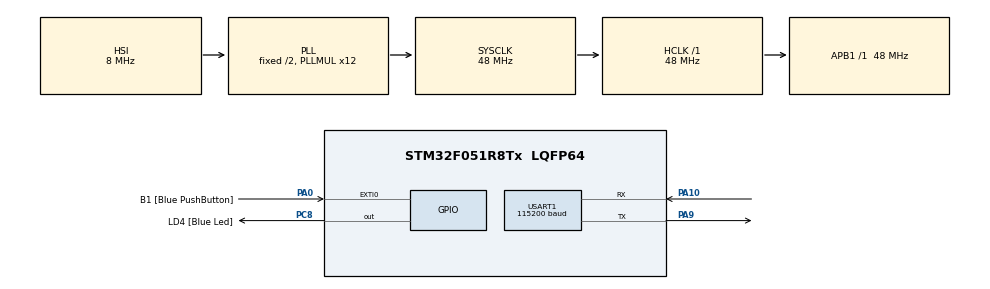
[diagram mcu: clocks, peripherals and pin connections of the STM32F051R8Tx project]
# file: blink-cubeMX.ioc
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Mcu.Family=STM32F0
Mcu.Name=STM32F051R8Tx
Mcu.Package=LQFP64
NVIC.TIM1_BRK_UP_TRG_COM_IRQn=true\:0\:0\:false\:false\:true\:true\:true\:true
PA0.GPIO_Label=B1 [Blue PushButton]
PA0.GPIO_ModeDefaultEXTI=GPIO_MODE_EVT_RISING
PA0.Signal=GPXTI0
PA10.Mode=Asynchronous
PA10.Signal=USART1_RX
PA13.GPIO_Label=SWDIO
PA13.Signal=SYS_SWDIO
PA9.Mode=Asynchronous
PA9.Signal=USART1_TX
PC8.GPIO_Label=LD4 [Blue Led]
PC8.Signal=GPIO_Output
ProjectManager.HeapSize=0x200
ProjectManager.StackSize=0x400
ProjectManager.TargetToolchain=Makefile
RCC.AHBFreq_Value=48000000
RCC.APB1Freq_Value=48000000
RCC.APB1TimFreq_Value=48000000
RCC.HCLKFreq_Value=48000000
RCC.PLLMUL=RCC_PLL_MUL12
RCC.SYSCLKFreq_VALUE=48000000
RCC.SYSCLKSource=RCC_SYSCLKSOURCE_PLLCLK
TIM1.AutoReloadPreload=TIM_AUTORELOAD_PRELOAD_DISABLE
TIM1.Period=65535
TIM1.TIM_MasterOutputTrigger=TIM_TRGO_RESET
USART1.BaudRate=115200
USART1.Mode=MODE_TX
USART1.VirtualMode-Asynchronous=VM_ASYNC
VP_TIM1_VS_ClockSourceINT.Mode=Internal
board=STM32F0DISCOVERY

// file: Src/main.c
/* USER CODE BEGIN Header */
/**
  ******************************************************************************
  * @file           : main.c
  * @brief          : Main program body
  ******************************************************************************
  * @attention
  *
  * Copyright (c) 2024 STMicroelectronics.
  * All rights reserved.
  *
  * This software is licensed under terms that can be found in the LICENSE file
  * in the root directory of this software component.
  * If no LICENSE file comes with this software, it is provided AS-IS.
  *
  ******************************************************************************
  */
/* USER CODE END Header */
#include "main.h"
#include "tim.h"
#include "usart.h"
#include "gpio.h"

void SystemClock_Config(void);

int main(void)
{

  /* MCU Configuration--------------------------------------------------------*/

  /* Reset of all peripherals, Initializes the Flash interface and the Systick. */
  HAL_Init();

  /* Configure the system clock */
  SystemClock_Config();

  /* Initialize all configured peripherals */
  MX_GPIO_Init();
  MX_USART1_UART_Init();
  MX_TIM1_Init();
  /* USER CODE BEGIN 2 */
	HAL_TIM_Base_Start_IT(&htim1);
  /* USER CODE END 2 */

  /* Infinite loop */
  /* USER CODE BEGIN WHILE */
	while (1) {
		HAL_GPIO_WritePin(LD4_GPIO_Port, LD4_Pin, GPIO_PIN_SET);
		printf("[%ld] LED ON\r\n", get_time_ms());
		delay_ms(1000);
		HAL_GPIO_WritePin(LD4_GPIO_Port, LD4_Pin, GPIO_PIN_RESET);
		printf("[%ld] LED OFF\r\n", get_time_ms());
		delay_ms(1000);
    /* USER CODE END WHILE */

	}
}

void SystemClock_Config(void)
{
  RCC_OscInitTypeDef RCC_OscInitStruct = {0};
  RCC_ClkInitTypeDef RCC_ClkInitStruct = {0};
  RCC_PeriphCLKInitTypeDef PeriphClkInit = {0};

  /** Initializes the RCC Oscillators according to the specified parameters
  * in the RCC_OscInitTypeDef structure.
  */
  RCC_OscInitStruct.OscillatorType = RCC_OSCILLATORTYPE_HSI;
  RCC_OscInitStruct.HSIState = RCC_HSI_ON;
  RCC_OscInitStruct.HSICalibrationValue = RCC_HSICALIBRATION_DEFAULT;
  RCC_OscInitStruct.PLL.PLLState = RCC_PLL_ON;
  RCC_OscInitStruct.PLL.PLLSource = RCC_PLLSOURCE_HSI;
  RCC_OscInitStruct.PLL.PLLMUL = RCC_PLL_MUL12;
  RCC_OscInitStruct.PLL.PREDIV = RCC_PREDIV_DIV1;
  if (HAL_RCC_OscConfig(&RCC_OscInitStruct) != HAL_OK)
  {
    Error_Handler();
  }

  /** Initializes the CPU, AHB and APB buses clocks
  */
  RCC_ClkInitStruct.ClockType = RCC_CLOCKTYPE_HCLK|RCC_CLOCKTYPE_SYSCLK
                              |RCC_CLOCKTYPE_PCLK1;
  RCC_ClkInitStruct.SYSCLKSource = RCC_SYSCLKSOURCE_PLLCLK;
  RCC_ClkInitStruct.AHBCLKDivider = RCC_SYSCLK_DIV1;
  RCC_ClkInitStruct.APB1CLKDivider = RCC_HCLK_DIV1;

  if (HAL_RCC_ClockConfig(&RCC_ClkInitStruct, FLASH_LATENCY_1) != HAL_OK)
  {
    Error_Handler();
  }
  PeriphClkInit.PeriphClockSelection = RCC_PERIPHCLK_USART1;
  PeriphClkInit.Usart1ClockSelection = RCC_USART1CLKSOURCE_PCLK1;
  if (HAL_RCCEx_PeriphCLKConfig(&PeriphClkInit) != HAL_OK)
  {
    Error_Handler();
  }
}

void Error_Handler(void)
{
  __disable_irq();
  while (1)
  {
  }
}
